# N575F145_v1 register map
File version: 1.0
N575F145_v1 SVD file
Registers are 32-bit, read-write, reset 0x0 unless marked. A register's access mark holds for its fields unless they carry their own. Offsets are from the block's base; lines under a group give offsets from that group; [hi:lo] are bit positions; {n}, {i} and the like mark numbered series; 'fields as' and 'values as' point back to an identical list; <NAME> marks a mode.

## Memory map
0x40004000 WDT size 0x4 — WDT Register Map
0x40008000 RTC size 0x34 — RTC Register Map
0x40010000 TMR0 size 0x10 — TMR Register Map
0x40010020 TMR1 size 0x10 — TMR Register Map
0x40020000 I2C size 0x34 — I2C Register Map
0x40030000 SPI0 blocks up to offset 0x3C — SPI0 Register Map
0x40040000 PWMA blocks up to offset 0x80 — PWMA Register Map
0x40050000 UART0 size 0x34 — UART0 Register Map
0x40070000 DPWM size 0x14 — DPWM Register Map
0x40080000 ANA blocks up to offset 0x9C — ANA Register Map
0x40084000 BOD size 0x14 — BOD Register Map
0x40090000 CRC size 0xC — CRC Register Map
0x400A0000 I2S size 0x18 — I2S Register Map
0x400B0000 BIQ blocks up to offset 0x44 — BIQ Register Map
0x400B0048 ALC size 0x10 — ALC Register Map
0x400D0000 ACMP size 0x10 — ACMP Register Map
0x400E0000 ADC size 0x20 — ADC Register Map
0x50000000 GCR blocks up to offset 0x118 — GCR Register Map
0x50000200 CLK size 0x2C — CLK Register Map
0x50000300 INT size 0x88 — INT Register Map
0x50004000 GP blocks up to offset 0x184 — GPIO Register Map
0x50008000 PDMA0 size 0x28 — PDMA Register Map
0x50008100 PDMA1 size 0x28 — PDMA Register Map
0x50008200 PDMA2 size 0x28 — PDMA Register Map
0x50008300 PDMA3 size 0x28 — PDMA Register Map
0x50008F00 PDMA_GCR blocks up to offset 0x10 — PDMA Register Map
0x5000C000 FMC size 0x18 — FMC Register Map
0xE000E000 SCS blocks up to offset 0xD24 — SCS Register Map

## BOD — BOD Register Map
Base 0x40084000
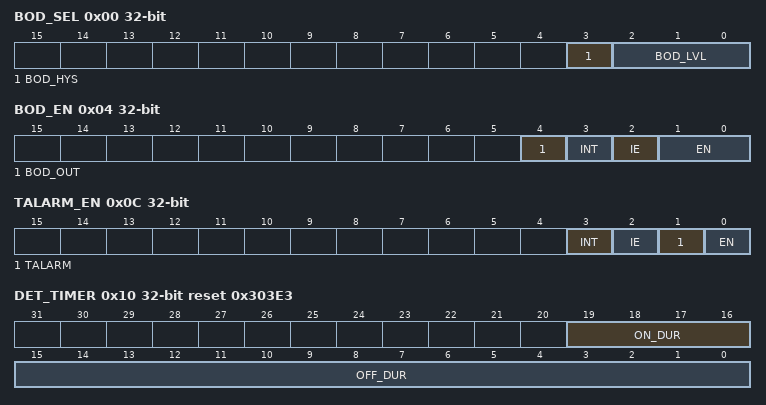
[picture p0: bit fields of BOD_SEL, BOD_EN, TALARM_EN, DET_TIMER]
0x00 BOD_SEL — Brown Out Detector Select Register
  [3] BOD_HYS — BOD Hysteresis
    0=Hysteresis Disabled; 1=Enable Hysteresis of BOD detection
  [2:0] BOD_LVL — BOD Voltage Level. 111b = 4.6V. 110b = 3.0V. 101b = 2.8V. 100b = 2.625V. 011b = 2.5V. 010b = 2.4V. 001b = 2.2V. 000b = 2.1V
0x04 BOD_EN (reset mask 0xFFFFFF00) — Brown Out Detector Enable Register
  [4] BOD_OUT — Output of BOD Detection Block. This signal can be monitored to determine the current state of the BOD comparator. Read '1' implies that VCC is less than BOD_LVL.
  [3] INT — Current Status Of Interrupt. Latched whenever a BOD event occurs and IE = 1. Write '1' to clear.
  [2] IE — BOD Interrupt Enable
    0=Disable BOD Interrupt; 1=Enable BOD Interrupt
  [1:0] EN — BOD Enable. 1xb = Enable continuous BOD detection. 01b = Enable time multiplexed BOD detection. See DET_TIMER register. 00b = Disable BOD Detection.
0x08 TALARM_SEL — Temperature Alarm Select Register
  [3:0] LVL — Temperature Alarm Sense Level. 0000:105C. 0001:115C. 0010:125C. 0100:135C. 1000:145C
0x0C TALARM_EN (reset mask 0xFFFFFF00) — Temperature Alarm Enable Register
  [3] INT — Current status of interrupt. Latched whenever a Temperature Sense event occurs and IE = 1. Write '1' to clear.
  [2] IE — TALARM Interrupt Enable
    0=Disable TALARM Interrupt; 1=Enable TALARM Interrupt
  [1] TALARM — Output of TALARM Block. Can be polled to determine whether TALARM active (be 1).
  [0] EN — TALARM Enable
    0=Disable TALARM Detection; 1=Enable TALARM Detection
0x10 DET_TIMER reset 0x303E3 — Brown Out Detector Timer Register
  [19:16] ON_DUR — Time BOD Detector Is Active (ON_DUR+1) * 100us. Minimum value is 1. (default is 400us)
  [15:0] OFF_DUR — Time BOD Detector Is Off (OFF_DUR+1)*100us . Minimum value is 7. (default is 99.6ms)

## TMR0 — TMR Register Map
Base 0x40010000
Same registers: TMR1 0x40010020
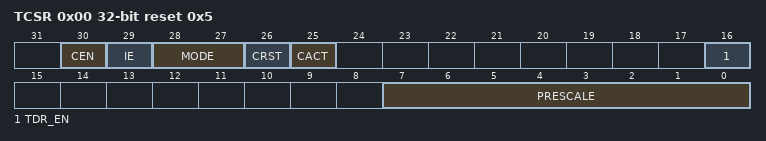
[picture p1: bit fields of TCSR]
0x00 TCSR reset 0x5 — Timer Control and Status Register
  [30] CEN — Counter Enable Bit. Note1: Setting CEN = 1 enables 24-bit counter. It continues count from last value. Note2: This bit is auto-cleared by hardware in one-shot mode (MODE = 00b) when the timer interrupt is generated (IE = 1b).
    0=Stops/Suspends counting; 1=Starts counting
  [29] IE — Interrupt Enable Bit. If timer interrupt is enabled, the timer asserts its interrupt signal when the count is equal to TCMPR.
    0=Disable TIMER Interrupt; 1=Enable TIMER Interrupt
  [28:27] MODE — Timer Operating Mode
    0=The timer is operating in the one-shot mode. The associated interrupt signal is generated once (if IE is enabled) and CEN is automatically cleared by hardware; 1=The timer is operating in the periodic mode. The associated interrupt signal is generated periodically (if IE is enabled); 3=The timer is operating in continuous counting mode. The associated interrupt signal is generated when TDR = TCMPR (if IE is enabled); however, the 24-bit up-counter counts continuously without reset
  [26] CRST — Counter Reset Bit. Set this bit will reset the timer counter, prescale and also force CEN to 0.
    0=No effect; 1=Reset Timer's prescale counter, internal 24-bit up-counter and CEN bit
  [25] CACT ro — Timer Active Status Bit (Read only). This bit indicates the counter status of timer.
    0=Timer is not active; 1=Timer is active
  [16] TDR_EN — Data Latch Enable. When TDR_EN is set, TDR (Timer Data Register) will be updated continuously with the 24-bit up-counter value as the timer is counting.
    0=Timer Data Register update disable; 1=Timer Data Register update enable
  [7:0] PRESCALE — Pre-scale Counter. Clock input is divided by PRESCALE+1 before it is fed to the counter. If PRESCALE = 0, then there is no scaling.
0x04 TCMPR — Timer Compare Register
  [24:0] TCMP — Timer Comparison Value. TCMP is a 24-bit comparison register. When the 24-bit up-counter is enabled and its value is equal to TCMP value, a Timer Interrupt is requested if the timer interrupt is enabled with TCSR.IE = 1. The TCMP value defines the timer cycle time. Time out period = (Period of timer clock input) * (8-bit PRESCALE + 1) * (24-bit TCMP). NOTE1: Never set TCMP to 0x000 or 0x001. Timer will not function correctly. NOTE2: Regardless of CEN state, whenever a new value is written to this register, TIMER will restart counting using this new value and abort previous count.
0x08 TISR — Timer Interrupt Status Register
  [0] TIF — Timer Interrupt Flag. This bit indicates the interrupt status of Timer. TIF bit is set by hardware when the 24-bit counter matches the timer comparison value (TCMP). It is cleared by writing 1.
0x0C TDR — Timer Data Register
  [23:0] TDR — Timer Data Register. When TCSR.TDR_EN is set to 1, the internal 24-bit timer up-counter value will be latched into TDR. User can read this register for the up-counter value.
